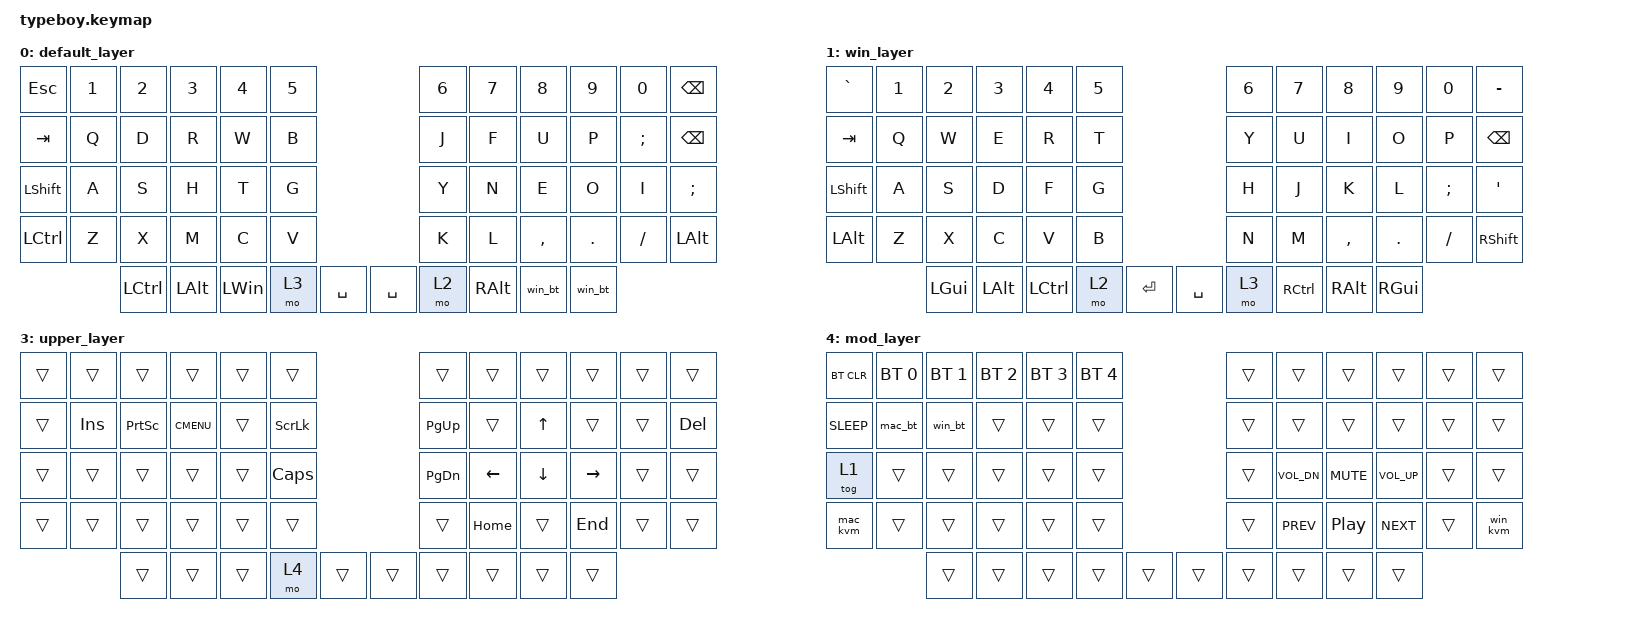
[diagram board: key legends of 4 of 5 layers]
#include <behaviors.dtsi>
#include <dt-bindings/zmk/keys.h>
#include <dt-bindings/zmk/bt.h>
#include <dt-bindings/zmk/outputs.h>

/{

    macros {
        mac_bt: mac_bt {
            label = "mac_bt";
            compatible = "zmk,behavior-macro";
            #binding-cells = <0>;
            bindings = <&macro_tap>, <&bt BT_SEL 0>, <&macro_tap>, <&tog 1>;
        };

        win_bt: win_bt {
            label = "win_bt";
            compatible = "zmk,behavior-macro";
            #binding-cells = <0>;
            bindings = <&macro_tap>, <&bt BT_SEL 1>, <&macro_tap>, <&tog 1>;
        };

        mac_kvm: mac_kvm {
            label = "mac_kvm";
            compatible = "zmk,behavior-macro";
            #binding-cells = <0>;
            bindings =
                <&macro_tap>,
                <&kp SLCK>,
                <&macro_wait_time 50>,
                <&macro_tap>,
                <&kp SLCK>,
                <&macro_wait_time 50>,
                <&macro_tap>,
                <&kp N1>,
                <&macro_tap>,
                <&to 0>;
        };

        win_kvm: win_kvm {
            label = "win_kvm";
            compatible = "zmk,behavior-macro";
            #binding-cells = <0>;
            bindings =
                <&macro_tap>,
                <&kp SLCK>,
                <&macro_wait_time 50>,
                <&macro_tap>,
                <&kp SLCK>,
                <&macro_wait_time 50>,
                <&macro_tap>,
                <&kp N2>,
                <&macro_tap>,
                <&to 1>;
        };
    };

    keymap {
        compatible = "zmk,keymap";

        default_layer {
            // ,-----------------------------------------.               ,-----------------------------------------.
            // |  `   |  1   |  2   |  3   |  4   |  5   |               |  6   |  7   |  8   |  9   |  0   |  -   |
            // |------+------+------+------+------+------|               |------+------+------+------+------+------|
            // | Esc  |  Q   |  D   |  R   |  W   |  B   |               |  J   |  F   |  U   |  P   |  ;   | BSPC |
            // |------+------+------+------+------+------|               |------+------+------+------+------+------|
            // | Tab  |  A   |  S   |  H   |  T   |  G   |               |  Y   |  N   |  E   |  O   |  I   |  '   |
            // |------+------+------+------+------+------+------. .------+------+------+------+------+------+------|
            // | Shift|  Z   |  X   |  M   |  C   |  V   |      | |      |  K   |  L   |  <   |  >   |  /   | Shift|
            // `-------------+------+------+------+------| Enter| | Space|------+------+------+------+------+------'
            //               | Ctrl | Alt  | Cmd  | Lower|      | |      | Raise| Cmd  | Alt  | Ctrl |
            //               `----------------------------------' '----------------------------------'

            bindings = <
&kp ESC         &kp N1  &kp N2     &kp N3        &kp N4        &kp N5                          &kp N6  &kp N7    &kp N8     &kp N9      &kp N0         &kp BACKSPACE
&kp TAB         &kp Q   &kp D      &kp R         &kp W         &kp B                           &kp J   &kp F     &kp U      &kp P       &kp SEMICOLON  &kp BSPC
&kp LEFT_SHIFT  &kp A   &kp S      &kp H         &kp T         &kp G                           &kp Y   &kp N     &kp E      &kp O       &kp I          &kp SEMI
&kp LCTRL       &kp Z   &kp X      &kp M         &kp C         &kp V                           &kp K   &kp L     &kp COMMA  &kp PERIOD  &kp SLASH      &kp LALT
                        &kp LCTRL  &kp LALT  &kp LEFT_WIN  &mo 3   &kp SPACE    &kp SPACE  &mo 2   &kp RALT  &win_bt    &win_bt
            >;
        };

        win_layer {
            // ,-----------------------------------------.               ,-----------------------------------------.
            // |  `   |  1   |  2   |  3   |  4   |  5   |               |  6   |  7   |  8   |  9   |  0   |  -   |
            // |------+------+------+------+------+------|               |------+------+------+------+------+------|
            // | Esc  |  Q   |  W   |  E   |  R   |  T   |               |  Y   |  U   |  I   |  O   |  P   | BSPC |
            // |------+------+------+------+------+------|               |------+------+------+------+------+------|
            // | Tab  |  A   |  S   |  D   |  F   |  G   |               |  H   |  J   |  K   |  L   |  ;   |  '   |
            // |------+------+------+------+------+------+------. .------+------+------+------+------+------+------|
            // | Shift|  Z   |  X   |  C   |  V   |  B   |      | |      |  N   |  M   |  ,   |  .   |  /   | Shift|
            // `-------------+------+------+------+------| Enter| | Space|------+------+------+------+------+------'
            //               | Ctrl | Alt  | Cmd  | Lower|      | |      | Raise| Cmd  | Alt  | Ctrl |
            //               `----------------------------------' '----------------------------------'

            bindings = <
&kp GRAVE  &kp N1  &kp N2  &kp N3     &kp N4  &kp N5                       &kp N6     &kp N7    &kp N8    &kp N9     &kp N0    &kp MINUS
&kp TAB    &kp Q   &kp W   &kp E      &kp R   &kp T                        &kp Y      &kp U     &kp I     &kp O      &kp P     &kp BSPC
&kp LSHFT  &kp A   &kp S   &kp D      &kp F   &kp G                        &kp H      &kp J     &kp K     &kp L      &kp SEMI  &kp SQT
&kp LALT  &kp Z   &kp X   &kp C      &kp V   &kp B    &kp N        &kp M  &kp COMMA  &kp DOT   &kp FSLH  &kp RSHFT  &kp LGUI  &kp LALT
                           &kp LCTRL  &mo 2   &kp RET  &kp SPACE    &mo 3  &kp RCTRL  &kp RALT  &kp RGUI
            >;
        };

        lower_layer {
            // ,-----------------------------------------.               ,-----------------------------------------.
            // |      |  F1  |  F2  |  F3  |  F4  |  F5  |               |  F6  |  F7  |  F8  |  F9  | F10  | F11  |
            // |------+------+------+------+------+------|               |------+------+------+------+------+------|
            // |      |  1   |  2   |  3   |  4   |  5   |               |  6   |  7   |  8   |  9   |  0   | F12  |
            // |------+------+------+------+------+------|               |------+------+------+------+------+------|
            // |      |  !   |  @   |  #   |  $   |  %   |               |  ^   |  &   |  *   |  (   |  )   |  |   |
            // |------+------+------+------+------+------+------. .------+------+------+------+------+------+------|
            // |      |  =   |  -   |  +   |  {   |  }   |      | |      |  [   |  ]   |  ;   |  :   |  \   |      |
            // `-------------+------+------+------+------|      | |      |------+------+------+------+------+------'
            //               |      |      |      |      |      | |      | Raise|      |      |      |
            //               `----------------------------------' '----------------------------------'

            bindings = <
&trans  &kp F1     &kp F2     &kp F3       &kp F4    &kp F5                           &kp F6     &kp F7     &kp F8     &kp F9    &kp F10   &kp F11
&trans  &kp N1     &kp N2     &kp N3       &kp N4    &kp N5                           &kp N6     &kp N7     &kp N8     &kp N9    &kp N0    &kp F12
&trans  &kp EXCL   &kp AT     &kp HASH     &kp DLLR  &kp PRCNT                        &kp CARET  &kp AMPS   &kp ASTRK  &kp LPAR  &kp RPAR  &kp PIPE
&kp F13 &kp F14    &kp F15    &kp F16      &kp F17   &kp F18                          &kp F19    &kp F20    &kp F21    &kp F22   &kp F23   &kp F24
                              &trans       &trans    &trans     &trans      &mo 4     &trans     &trans     &trans
            >;
        };

        upper_layer {
            // ,-----------------------------------------.               ,-----------------------------------------.
            // |      |      |      |      |      |      |               |      |      |      |      |      |      |
            // |------+------+------+------+------+------|               |------+------+------+------+------+------|
            // |      | INS  | PSCRN| MENU |      | Scll |               | PG UP|      |  Up  |      |      | Del  |
            // |------+------+------+------+------+------|               |------+------+------+------+------+------|
            // |      |      |      |      |      | Caps |               | PG DN| Left | Down | Right|      |      |
            // |------+------+------+------+------+------+------. .------+------+------+------+------+------+------|
            // |      |      |      |      |      |      |      | |      |      | LStr |      | LEnd |      |      |
            // `-------------+------+------+------+------|      | |      |------+------+------+------+------+------'
            //               |      |      |      | Lower|      | |      |      |      |      |      |
            //               `----------------------------------' '----------------------------------'

            bindings = <
&trans  &trans   &trans     &trans       &trans  &trans                        &trans     &trans    &trans    &trans     &trans  &trans
&trans  &kp INS  &kp PSCRN  &kp K_CMENU  &trans  &kp SLCK                      &kp PG_UP  &trans    &kp UP    &trans     &trans  &kp DEL
&trans  &trans   &trans     &trans       &trans  &kp CLCK                      &kp PG_DN  &kp LEFT  &kp DOWN  &kp RIGHT  &trans  &trans
&trans  &trans   &trans     &trans       &trans  &trans    &trans    &kp HOME  &trans     &kp END   &trans    &trans     &trans  &trans
                            &trans       &mo 4   &trans    &trans    &trans    &trans     &trans    &trans
            >;
        };

        mod_layer {
            // ,-----------------------------------------.               ,-----------------------------------------.
            // |BT CLR| BT1  | BT2  | BT3  | BT4  | BT5  |               |      |      |      |      |      |      |
            // |------+------+------+------+------+------|               |------+------+------+------+------+------|
            // | Sleep|      |      |      |      |      |               |      |      |      |      |      |      |
            // |------+------+------+------+------+------|               |------+------+------+------+------+------|
            // |      |      |      |      |      |      |               |      | VolDn| Mute | VolUp|      |      |
            // |------+------+------+------+------+------+------. .------+------+------+------+------+------+------|
            // |      |      |      |      |      |      |      | |      |      | Prev | Play | Next |      |      |
            // `-------------+------+------+------+------|      | |      |------+------+------+------+------+------'
            //               |      |      |      |      |      | |      |      |      |      |      |
            //               `----------------------------------' '----------------------------------'

            bindings = <
&bt BT_CLR   &bt BT_SEL 0  &bt BT_SEL 1  &bt BT_SEL 2  &bt BT_SEL 3  &bt BT_SEL 4                        &trans    &trans        &trans      &trans        &trans  &trans
&kp K_SLEEP  &mac_bt       &win_bt       &trans        &trans        &trans                              &trans    &trans        &trans      &trans        &trans  &trans
&tog 1       &trans        &trans        &trans        &trans        &trans                              &trans    &kp C_VOL_DN  &kp C_MUTE  &kp C_VOL_UP  &trans  &trans
&mac_kvm     &trans        &trans        &trans        &trans        &trans        &trans    &kp C_PREV  &kp C_PP  &kp C_NEXT    &trans      &win_kvm      &trans  &trans
                                         &trans        &trans        &trans        &trans    &trans      &trans    &trans        &trans
            >;
        };
    };
};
